# PIC32MZ1064DAR176 register map
Vendor: Microchip
Registers are 32-bit, read-write, reset 0x0 unless marked. A register's access mark holds for its fields unless they carry their own. Addresses are absolute, and some are shared; only a register's first bit layout is shown; [hi:lo] are bit positions; {n}, {i} and the like mark numbered series; 'fields as' and 'values as' point back to an identical list.

## DOS_EIP_00184_emb_ddr_controller
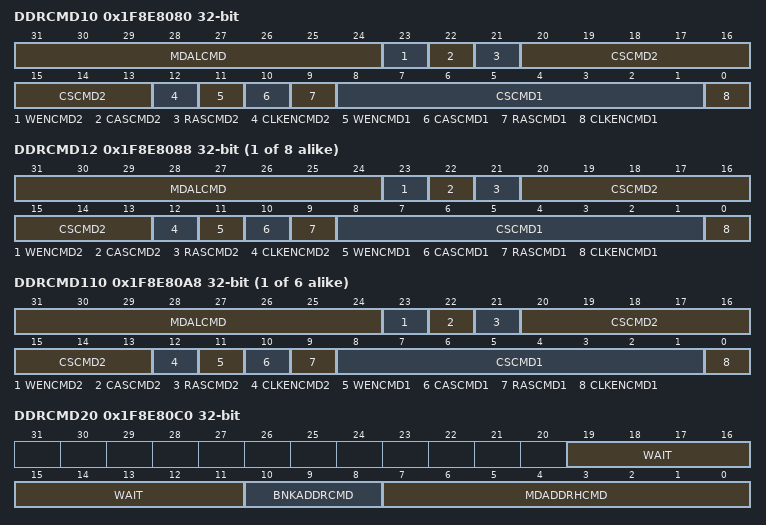
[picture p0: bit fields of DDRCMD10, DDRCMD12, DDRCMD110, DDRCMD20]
0x1F8E8080 DDRCMD10 reset not defined — (power-on value xxxxxxxxxxxxxxxxxxxx000000000000)
  [31:24] MDALCMD, [23] WENCMD2, [22] CASCMD2, [21] RASCMD2, [20:13] CSCMD2, [12] CLKENCMD2, [11] WENCMD1, [10] CASCMD1, [9] RASCMD1, [8:1] CSCMD1, [0] CLKENCMD1
{0x1F8E8058+4i} DDRCMD{i} reset not defined (i=12..19) — (power-on value xxxxxxxxxxxxxxxxxxxx000000000000)
  fields as DDRCMD10
{0x1F8E7EF0+4i} DDRCMD{i} reset not defined (i=110..115) — (power-on value xxxxxxxxxxxxxxxxxxxx000000000000)
  fields as DDRCMD10
0x1F8E80C0 DDRCMD20
  [19:11] WAIT, [10:8] BNKADDRCMD, [7:0] MDADDRHCMD
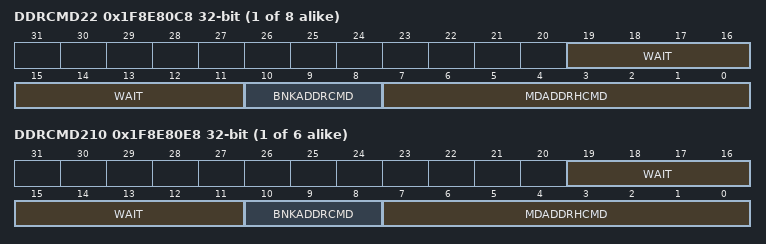
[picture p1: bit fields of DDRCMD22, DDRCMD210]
{0x1F8E8070+4i} DDRCMD{i} (i=22..29)
  [19:11] WAIT, [10:8] BNKADDRCMD, [7:0] MDADDRHCMD
{0x1F8E7DA0+4i} DDRCMD{i} (i=210..215)
  [19:11] WAIT, [10:8] BNKADDRCMD, [7:0] MDADDRHCMD

## DDR_PHY
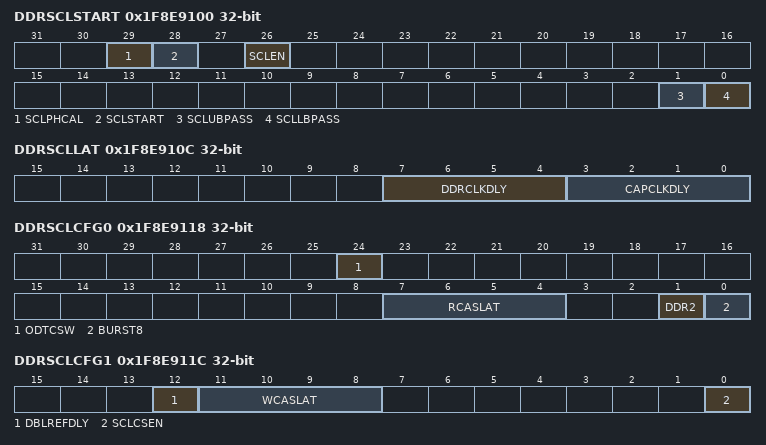
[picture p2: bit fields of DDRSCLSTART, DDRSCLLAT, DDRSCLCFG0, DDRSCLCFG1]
0x1F8E9100 DDRSCLSTART reset not defined — (power-on value --00-0------------------------xx)
  [29] SCLPHCAL, [28] SCLSTART, [26] SCLEN, [1] SCLUBPASS ro, [0] SCLLBPASS ro
0x1F8E910C DDRSCLLAT
  [7:4] DDRCLKDLY, [3:0] CAPCLKDLY
0x1F8E9118 DDRSCLCFG0
  [24] ODTCSW, [7:4] RCASLAT, [1] DDR2, [0] BURST8
0x1F8E911C DDRSCLCFG1 reset not defined — (power-on value -------------------xxxxx-------0)
  [12] DBLREFDLY, [11:8] WCASLAT, [0] SCLCSEN
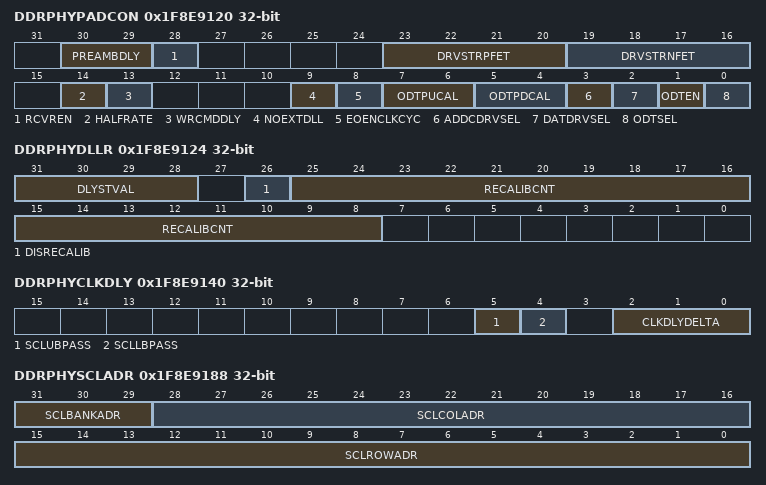
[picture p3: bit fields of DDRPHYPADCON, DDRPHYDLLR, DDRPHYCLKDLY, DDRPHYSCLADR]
0x1F8E9120 DDRPHYPADCON
  [30:29] PREAMBDLY, [28] RCVREN, [23:20] DRVSTRPFET, [19:16] DRVSTRNFET, [14] HALFRATE, [13] WRCMDDLY, [9] NOEXTDLL, [8] EOENCLKCYC, [7:6] ODTPUCAL, [5:4] ODTPDCAL, [3] ADDCDRVSEL, [2] DATDRVSEL, [1] ODTEN, [0] ODTSEL
0x1F8E9124 DDRPHYDLLR
  [31:28] DLYSTVAL, [26] DISRECALIB, [25:8] RECALIBCNT
0x1F8E9128 DDRPHYDLLCTRL
  [7:0] DDRDLLTRIM
0x1F8E9140 DDRPHYCLKDLY reset not defined — (power-on value --------------------------xx-000)
  [5] SCLUBPASS ro, [4] SCLLBPASS ro, [2:0] CLKDLYDELTA
0x1F8E915C DDRADLLBYP
  [24] ANLDLLBYP
0x1F8E916C DDRSCLCFG2
  [1:0] SCLLANSEL
0x1F8E9188 DDRPHYSCLADR
  [31:29] SCLBANKADR, [28:16] SCLCOLADR, [15:0] SCLROWADR

## DOS_EIP_00160_gfx_gdc_ctlr
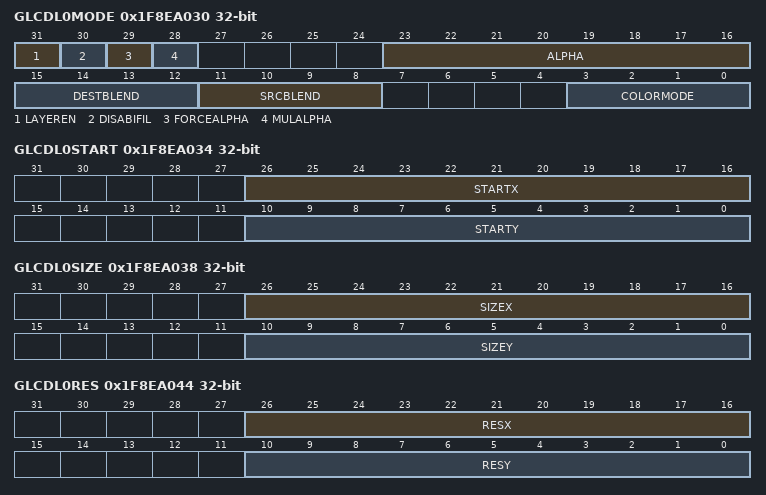
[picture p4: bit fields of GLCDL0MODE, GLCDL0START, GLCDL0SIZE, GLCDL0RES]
0x1F8EA030 GLCDL0MODE
  [31] LAYEREN, [30] DISABIFIL, [29] FORCEALPHA, [28] MULALPHA, [23:16] ALPHA, [15:12] DESTBLEND, [11:8] SRCBLEND, [3:0] COLORMODE
0x1F8EA034 GLCDL0START
  [26:16] STARTX, [10:0] STARTY
0x1F8EA038 GLCDL0SIZE
  [26:16] SIZEX, [10:0] SIZEY
0x1F8EA03C GLCDL0BADDR
  [31:0] BASEADDR
0x1F8EA040 GLCDL0STRIDE
  [15:0] STRIDE
0x1F8EA044 GLCDL0RES
  [26:16] RESX, [10:0] RESY
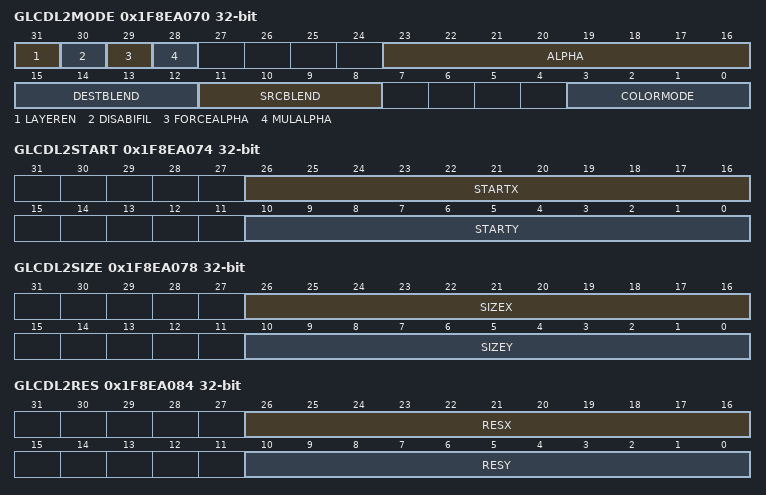
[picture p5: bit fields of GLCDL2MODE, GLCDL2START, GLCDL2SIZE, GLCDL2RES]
0x1F8EA070 GLCDL2MODE
  fields as GLCDL0MODE
0x1F8EA074 GLCDL2START
  [26:16] STARTX, [10:0] STARTY
0x1F8EA078 GLCDL2SIZE
  [26:16] SIZEX, [10:0] SIZEY
0x1F8EA07C GLCDL2BADDR
  [31:0] BASEADDR
0x1F8EA080 GLCDL2STRIDE
  [15:0] STRIDE
0x1F8EA084 GLCDL2RES
  [26:16] RESX, [10:0] RESY
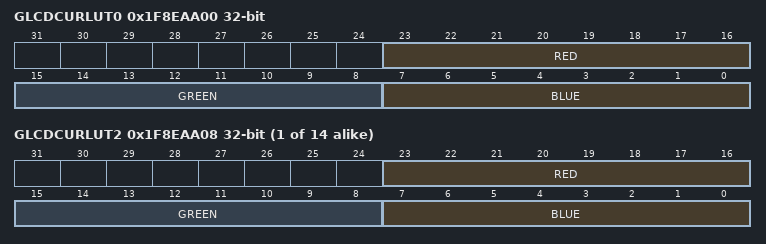
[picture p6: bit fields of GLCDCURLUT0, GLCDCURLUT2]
0x1F8EAA00 GLCDCURLUT0
  [23:16] RED, [15:8] GREEN, [7:0] BLUE
{0x1F8EAA00+4i} GLCDCURLUT{i} (i=2..15)
  [23:16] RED, [15:8] GREEN, [7:0] BLUE

## GPU
0x1F8EB000 GPUBASEADDR

## SDHC
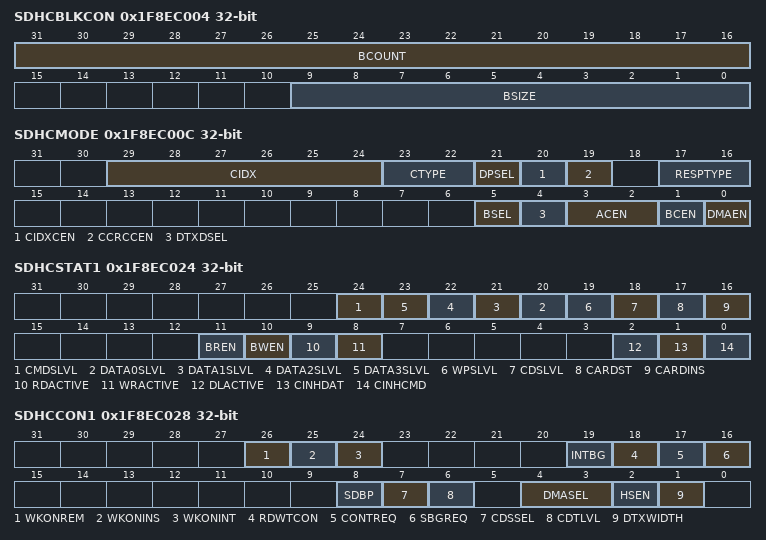
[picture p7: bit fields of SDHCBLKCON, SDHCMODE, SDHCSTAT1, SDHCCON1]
0x1F8EC004 SDHCBLKCON
  [31:16] BCOUNT, [9:0] BSIZE
0x1F8EC008 SDHCARG
  [31:0] ARG
0x1F8EC00C SDHCMODE
  [29:24] CIDX, [23:22] CTYPE, [21] DPSEL, [20] CIDXCEN, [19] CCRCCEN, [17:16] RESPTYPE, [5] BSEL, [4] DTXDSEL, [3:2] ACEN, [1] BCEN, [0] DMAEN
0x1F8EC014 SDHCRESP1 ro
  [31:0] RESP
0x1F8EC020 SDHCDATA
  [31:0] DATA
0x1F8EC024 SDHCSTAT1 ro reset not defined — (power-on value -------xxxxxxxxx----0000-----000)
  [24] CMDSLVL, [n+20] DATA{n}SLVL (n=0..3), [19] WPSLVL, [18] CDSLVL, [17] CARDST, [16] CARDINS, [11] BREN, [10] BWEN, [9] RDACTIVE, [8] WRACTIVE, [2] DLACTIVE, [1] CINHDAT, [0] CINHCMD
0x1F8EC028 SDHCCON1
  [26] WKONREM, [25] WKONINS, [24] WKONINT, [19] INTBG, [18] RDWTCON, [17] CONTREQ, [16] SBGREQ, [8] SDBP, [7] CDSSEL, [6] CDTLVL, [4:3] DMASEL, [2] HSEN, [1] DTXWIDTH
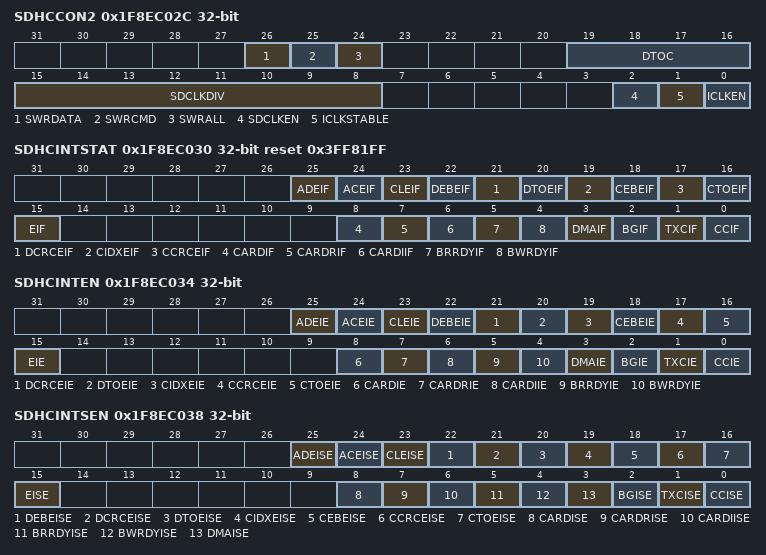
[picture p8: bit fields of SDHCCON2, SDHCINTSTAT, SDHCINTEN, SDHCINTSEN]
0x1F8EC02C SDHCCON2
  [26] SWRDATA, [25] SWRCMD, [24] SWRALL, [19:16] DTOC, [15:8] SDCLKDIV, [2] SDCLKEN, [1] ICLKSTABLE, [0] ICLKEN
0x1F8EC030 SDHCINTSTAT ro reset 0x3FF81FF
  [25] ADEIF, [24] ACEIF, [23] CLEIF, [22] DEBEIF, [21] DCRCEIF, [20] DTOEIF, [19] CIDXEIF, [18] CEBEIF, [17] CCRCEIF, [16] CTOEIF, [15] EIF, [8] CARDIF, [7] CARDRIF, [6] CARDIIF, [5] BRRDYIF, [4] BWRDYIF, [3] DMAIF, [2] BGIF, [1] TXCIF, [0] CCIF
0x1F8EC034 SDHCINTEN
  [25] ADEIE, [24] ACEIE, [23] CLEIE, [22] DEBEIE, [21] DCRCEIE, [20] DTOEIE, [19] CIDXEIE, [18] CEBEIE, [17] CCRCEIE, [16] CTOEIE, [15] EIE, [8] CARDIE, [7] CARDRIE, [6] CARDIIE, [5] BRRDYIE, [4] BWRDYIE, [3] DMAIE, [2] BGIE, [1] TXCIE, [0] CCIE
0x1F8EC038 SDHCINTSEN
  [25] ADEISE, [24] ACEISE, [23] CLEISE, [22] DEBEISE, [21] DCRCEISE, [20] DTOEISE, [19] CIDXEISE, [18] CEBEISE, [17] CCRCEISE, [16] CTOEISE, [15] EISE, [8] CARDISE, [7] CARDRISE, [6] CARDIISE, [5] BRRDYISE, [4] BWRDYISE, [3] DMAISE, [2] BGISE, [1] TXCISE, [0] CCISE
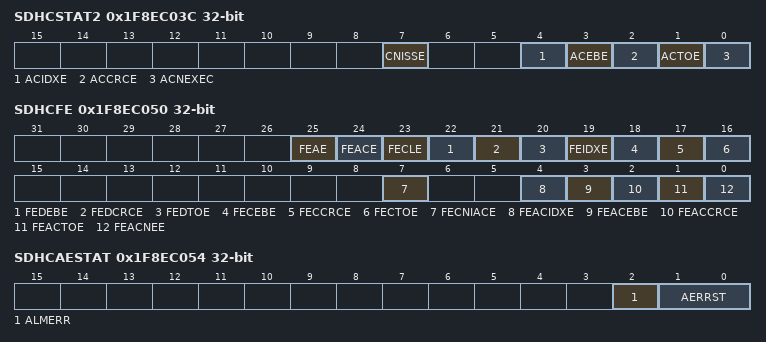
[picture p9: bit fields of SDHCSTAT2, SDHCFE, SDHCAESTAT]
0x1F8EC03C SDHCSTAT2 ro
  [7] CNISSE, [4] ACIDXE, [3] ACEBE, [2] ACCRCE, [1] ACTOE, [0] ACNEXEC
0x1F8EC040 SDHCCAP ro reset not defined — (power-on value -------1x-x-x-00--xxxxxx0-000000)
  [33:32] SLOTTYPE, [31] ASYNCINT, [26] VOLT3V3, [25] SRESUME, [23] HISPEED, [21] ADMA2, [20] BUS8BIT, [19:18] MBLEN, [15:8] BASECLK, [7] TOCLKU, [5:0] TOCLKFREQ
0x1F8EC048 SDHCMAXCAP ro reset not defined — (power-on value ------------------------xxxxxxxx)
  [7:0] MC3V3
0x1F8EC050 SDHCFE wo reset not defined — (power-on value ------xxxxxxxxxx--------x--xxxxx)
  [25] FEAE, [24] FEACE, [23] FECLE, [22] FEDEBE, [21] FEDCRCE, [20] FEDTOE, [19] FEIDXE, [18] FECEBE, [17] FECCRCE, [16] FECTOE, [7] FECNIACE, [4] FEACIDXE, [3] FEACEBE, [2] FEACCRCE, [1] FEACTOE, [0] FEACNEE
0x1F8EC054 SDHCAESTAT ro
  [2] ALMERR, [1:0] AERRST
0x1F8EC058 SDHCAADDR
  [31:0] ADDR

## DOS_EIP_00187_emb_sdio
0x1F8EC010 SDHCRESP0 ro
  [31:0] RESP
0x1F8EC018 SDHCRESP2 ro
  [31:0] RESP
0x1F8EC01C SDHCRESP3 ro
  [31:0] RESP

## SB
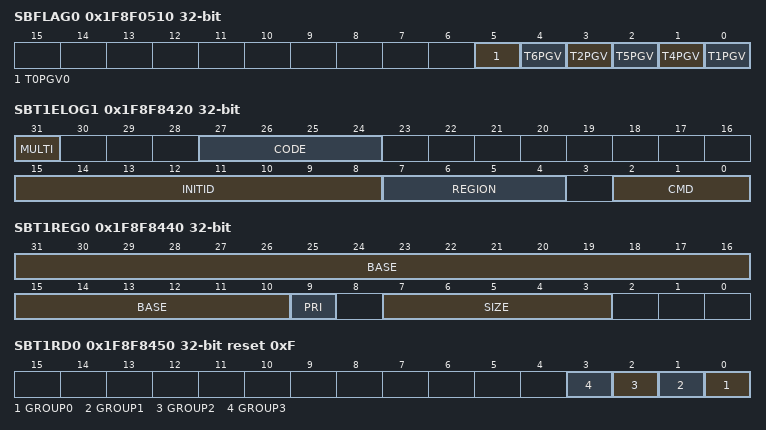
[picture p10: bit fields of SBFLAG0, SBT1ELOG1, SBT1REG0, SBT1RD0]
0x1F8F0510 SBFLAG0 ro
  [5] T0PGV0, [4] T6PGV, [3] T2PGV, [2] T5PGV, [1] T4PGV, [0] T1PGV
0x1F8F8420 SBT1ELOG1
  [31] MULTI, [27:24] CODE, [15:8] INITID ro, [7:4] REGION ro, [2:0] CMD ro
0x1F8F8424 SBT1ELOG2 ro
  [1:0] GROUP
0x1F8F8428 SBT1ECON
  [24] ERRP
0x1F8F8430 SBT1ECLRS ro
  [0] CLEAR
0x1F8F8438 SBT1ECLRM ro
  [0] CLEAR
0x1F8F8440 SBT1REG0 reset not defined — (power-on value 0000000000000000000000x-00000---)
  [31:10] BASE, [9] PRI ro, [7:3] SIZE
0x1F8F8450 SBT1RD0 reset 0xF
  [n] GROUP{n} (n=0..3)
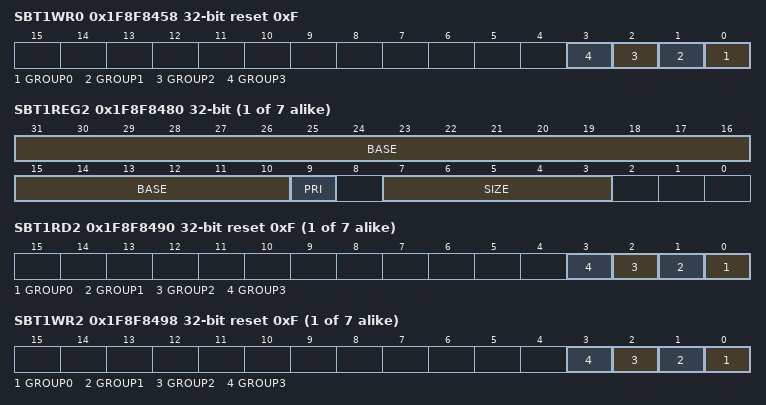
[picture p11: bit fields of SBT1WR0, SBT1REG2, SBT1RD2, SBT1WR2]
0x1F8F8458 SBT1WR0 reset 0xF
  [n] GROUP{n} (n=0..3)
{0x1F8F8440+0x20*i} SBT1REG{i} reset not defined (i=2..8) — (power-on value 0000000000000000000000x-00000---)
  [31:10] BASE, [9] PRI ro, [7:3] SIZE
{0x1F8F8450+0x20*i} SBT1RD{i} reset 0xF (i=2..8)
  [n] GROUP{n} (n=0..3)
{0x1F8F8458+0x20*i} SBT1WR{i} reset 0xF (i=2..8)
  [n] GROUP{n} (n=0..3)
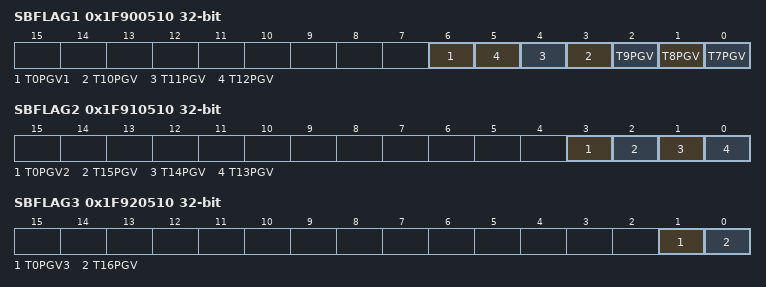
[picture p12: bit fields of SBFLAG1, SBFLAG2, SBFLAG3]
0x1F900510 SBFLAG1 ro
  [6] T0PGV1, [n-7] T{n}PGV (n=7..12)
0x1F910510 SBFLAG2 ro
  [3] T0PGV2, [2] T15PGV, [1] T14PGV, [0] T13PGV
0x1F920510 SBFLAG3 ro
  [1] T0PGV3, [0] T16PGV
